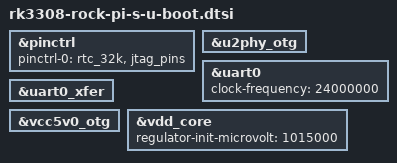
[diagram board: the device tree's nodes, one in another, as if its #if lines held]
// SPDX-License-Identifier: GPL-2.0+
/*
 * (C) Copyright 2018-2019 Rockchip Electronics Co., Ltd
 */
#include "rk3308-u-boot.dtsi"

#ifdef CONFIG_ROCKCHIP_RK3308_DEBUG_JTAG
/* Keep SWD on GPIO1_C6/C7 usable while U-Boot runs */
&pinctrl {
	pinctrl-names = "default";
	/* keep the board hog (rtc_32k) from rk3308-rock-pi-s.dts */
	pinctrl-0 = <&rtc_32k &jtag_pins>;
};
#endif

&u2phy_otg {
	/delete-property/ phy-supply;
};

&uart0 {
	bootph-all;
	clock-frequency = <24000000>;
};

&uart0_xfer {
	bootph-all;
};

&vcc5v0_otg {
	/delete-property/ regulator-always-on;
};

&vdd_core {
	regulator-init-microvolt = <1015000>;
};
